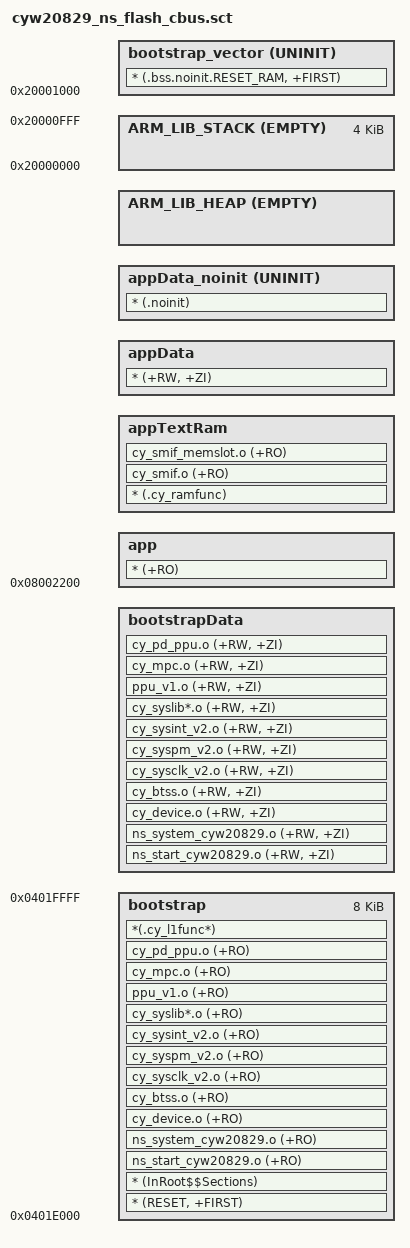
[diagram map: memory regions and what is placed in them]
#! armclang -E  --target=arm-arm-none-eabi -x c -mcpu=cortex-m33 -march=armv8-m.main
; The first line specifies a preprocessor command that the linker invokes
; to pass a scatter file through a C preprocessor.

/***************************************************************************//**
* \file cyw20829_ns_flash_cbus.sct
* \version 1.0.0
*
* Linker file for the ARMCC compiler.
*
* The main purpose of the linker script is to describe how the sections in the
* input files should be mapped into the output file, and to control the memory
* layout of the output file.
*
* \note The entry point location starts at 0x0401e000. The valid
* application image should be placed there.
*
* \note The linker files included with the PDL template projects must be generic
* and handle all common use cases. Your project may not use every section
* defined in the linker files. In that case you may see warnings during the
* build process. In your project, you can simply comment out or remove the
* relevant code in the linker file.
*
********************************************************************************
* \copyright
* Copyright (c) (2020-2022), Cypress Semiconductor Corporation (an Infineon company) or
* an affiliate of Cypress Semiconductor Corporation.
* SPDX-License-Identifier: Apache-2.0
*
* Licensed under the Apache License, Version 2.0 (the "License");
* you may not use this file except in compliance with the License.
* You may obtain a copy of the License at
*
*     http://www.apache.org/licenses/LICENSE-2.0
*
* Unless required by applicable law or agreed to in writing, software
* distributed under the License is distributed on an "AS IS" BASIS,
* WITHOUT WARRANTIES OR CONDITIONS OF ANY KIND, either express or implied.
* See the License for the specific language governing permissions and
* limitations under the License.
*******************************************************************************/

#define flash_start_addr_cbus 0x08000000
#define ram_start_addr_sahb 0x20000000
#define ram_start_addr_cbus 0x04000000
#define ram_end_addr_sahb 0x20020000

#define app_code_offset_flash 0x00002200
#define bootstrap_offset_ram 0x0001E000

; The size of the stack section at the end of CM33 SRAM
#define STACK_SIZE              0x00001000


/* VMA for bootstrap Text */
#define bootstrapText_vma ram_start_addr_cbus + bootstrap_offset_ram /* 0x0401E000 */
/* Size of bootstrap section */
#define bootstrapText_size 0x00002000

/* VMA for bootstrap Data */
#define bootstrapRamVect_vma ram_start_addr_sahb + STACK_SIZE /* 0x20001000 */

/* VMA for flash */
#define appText_vma flash_start_addr_cbus + app_code_offset_flash /* 0x08002200 */

/* Memory reserved for Bootstrap code and data */
#define BOOTSTRAP_SIZE ram_end_addr_sahb - ram_start_addr_sahb - bootstrap_offset_ram; /* 0x00002000 */

; Cortex-M33 application flash area
LR_1 bootstrapText_vma BOOTSTRAP_SIZE
{
    bootstrap bootstrapText_vma bootstrapText_size
    {
        * (RESET, +FIRST)
        * (InRoot$$Sections)

        ns_start_cyw20829.o (+RO)
        ns_system_cyw20829.o (+RO)

        /* drivers */
        cy_device.o (+RO)
        cy_btss.o (+RO)
        cy_sysclk_v2.o (+RO)
        cy_syspm_v2.o (+RO)
        cy_sysint_v2.o (+RO)
        cy_syslib*.o (+RO)
        ppu_v1.o (+RO)
        cy_mpc.o (+RO)
        cy_pd_ppu.o (+RO)
        *(.cy_l1func*)
    }

/* converting c-bus to sahb address */
#define bootstrapData_vma AlignExpr((ImageLimit(bootstrap) - ram_start_addr_cbus) + ram_start_addr_sahb, 4)

    bootstrapData bootstrapData_vma ALIGN 4
    {
        ns_start_cyw20829.o (+RW, +ZI)
        ns_system_cyw20829.o (+RW, +ZI)

        /* drivers */
        cy_device.o (+RW, +ZI)
        cy_btss.o (+RW, +ZI)
        cy_sysclk_v2.o (+RW, +ZI)
        cy_syspm_v2.o (+RW, +ZI)
        cy_sysint_v2.o (+RW, +ZI)
        cy_syslib*.o (+RW, +ZI)
        ppu_v1.o (+RW, +ZI)
        cy_mpc.o (+RW, +ZI)
        cy_pd_ppu.o (+RW, +ZI)
    }

    bootstrap_vector bootstrapRamVect_vma UNINIT
    {
        * (.bss.noinit.RESET_RAM, +FIRST)
    }
}

#define appTextRam_vma AlignExpr(ImageLimit( bootstrap_vector), 8)

LR_2 appText_vma
{
    app appText_vma
    {
        * (+RO)
    }

    appTextRam appTextRam_vma
    {
        * (.cy_ramfunc)
        cy_smif.o (+RO)
        cy_smif_memslot.o (+RO)
    }

#define appData_vma AlignExpr((ImageLimit(appTextRam) - ImageBase(appTextRam) + ImageLimit(bootstrap_vector)), 8)

    appData appData_vma
    {
        * (+RW, +ZI)
    }

    ; Place variables in the section that should not be initialized during the
    ; device startup.
    appData_noinit +0 UNINIT
    {
        * (.noinit)
    }

    ; Application heap area (HEAP)
    ARM_LIB_HEAP  +0 ALIGN 8 EMPTY ((ram_start_addr_sahb + bootstrap_offset_ram)-AlignExpr(ImageLimit(appData_noinit), 8))
    {
    }

    ; Stack region growing down
    ARM_LIB_STACK (ram_start_addr_sahb + STACK_SIZE) ALIGN 32 EMPTY -STACK_SIZE
    {
    }
}
/* [] END OF FILE */
